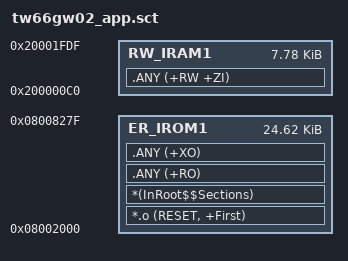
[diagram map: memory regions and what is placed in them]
LR_IROM1 0x08002000 0x00006280 {
  ER_IROM1 0x08002000 0x00006280 {
    *.o (RESET, +First)
    *(InRoot$$Sections)
    .ANY (+RO)
    .ANY (+XO)
  }
  RW_IRAM1 0x200000C0 0x00001F20 {
    .ANY (+RW +ZI)
  }
}
